# CC3220SF register map
Vendor: Texas Instruments; Series: Wireless Connectivity MCU; File version: 1
CPU: CM4 r1p0, little endian, no MPU, no FPU, 8 interrupt priority bits
Registers are 32-bit, read-write, reset 0x0 unless marked. A register's access mark holds for its fields unless they carry their own. Offsets are from the block's base; [hi:lo] are bit positions; {n}, {i} and the like mark numbered series.

## I2CA0
Base 0x40020000
0x00 MSA
  [7:1] SA — I2C Slave Address
0x04 MCS
0x08 MDR
  [7:0] DATA — Data Transferred
0x0C MTPR
  [6:0] TPR — SCL Clock Period
0x10 MIMR
0x14 MRIS
0x18 MMIS
0x1C MICR
0x20 MCR
0x24 MCLKOCNT
  [7:0] CNTL — I2C Master Count
0x2C MBMON
0x30 MBLEN
  [7:0] CNTL — I2C Burst Length
0x34 MBCNT
  [7:0] CNTL — I2C Master Burst Count
0x800 SOAR
  [6:0] OAR — I2C Slave Own Address
0x804 SCSR
0x808 SDR
  [7:0] DATA — Data for Transfer
0x80C SIMR
0x810 SRIS
0x814 SMIS
0x818 SICR
0x81C SOAR2
  [6:0] OAR2 — I2C Slave Own Address 2
0x820 SACKCTL
0xF00 FIFODATA
  [7:0] DATA — I2C FIFO Data Byte
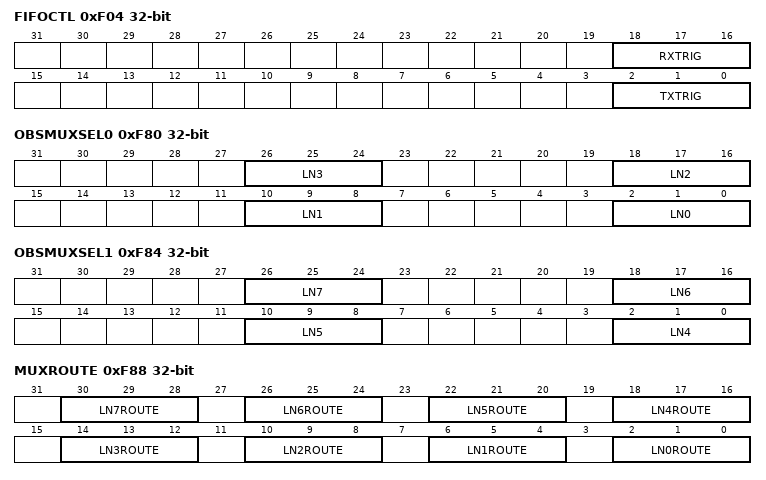
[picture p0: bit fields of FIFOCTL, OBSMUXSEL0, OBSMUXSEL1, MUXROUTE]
0xF04 FIFOCTL
  [18:16] RXTRIG — RX FIFO Trigger
  [2:0] TXTRIG — TX FIFO Trigger
0xF08 FIFOSTATUS
0xF80 OBSMUXSEL0
  [8n+2:8n] LN{n} (n=0..3) — Observation Mux Lane {n}
0xF84 OBSMUXSEL1
  [8n-30:8n-32] LN{n} (n=4..7) — Observation Mux Lane {n}
0xF88 MUXROUTE
  [4n+2:4n] LN{n}ROUTE (n=0..7) — Lane {n} output is routed to the lane pointed to by the offset in this bit field
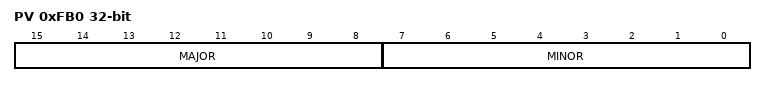
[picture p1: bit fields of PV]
0xFB0 PV
  [15:8] MAJOR — Major Revision
  [7:0] MINOR — Minor Revision
0xFC0 PP
0xFC4 PC
0xFC8 CC

## TIMERA0
Base 0x40030000
Same registers: TIMERA1 0x40031000, TIMERA2 0x40032000, TIMERA3 0x40033000
0x00 CFG — GPTM Configuration
  [2:0] CFG
0x04 TAMR — GPTM Timer A Mode
  [1:0] TAMR
0x08 TBMR — GPTM Timer B Mode
  [1:0] TBMR
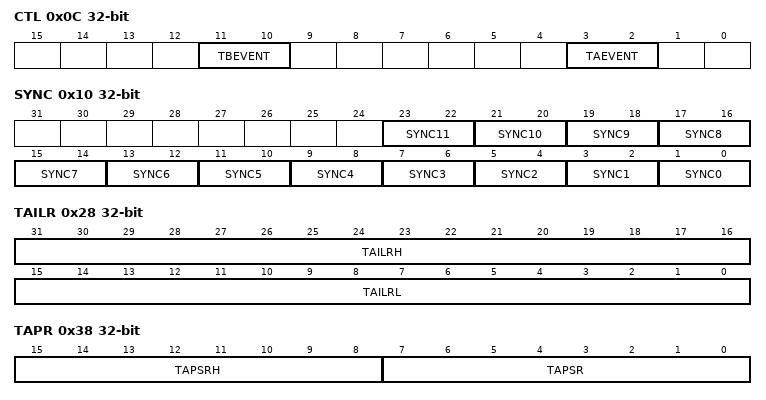
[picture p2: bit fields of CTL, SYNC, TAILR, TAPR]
0x0C CTL — GPTM Control ##### GARNET BEGIN #####
  [11:10] TBEVENT — GPTM Timer B Event Mode
  [3:2] TAEVENT — GPTM Timer A Event Mode
0x10 SYNC — GPTM Synchronize ##### GARNET END #####
  [2n+1:2n] SYNC{n} (n=0..11) — Synchronize GPTM Timer {n}
0x18 IMR — GPTM Interrupt Mask
0x1C RIS — GPTM Raw Interrupt Status
0x20 MIS — GPTM Masked Interrupt Status
0x24 ICR — GPTM Interrupt Clear
0x28 TAILR — GPTM Timer A Interval Load
  [31:16] TAILRH — GPTM Timer A Interval Load Register High
  [15:0] TAILRL — GPTM Timer A Interval Load Register Low
0x2C TBILR — GPTM Timer B Interval Load
  [15:0] TBILRL — GPTM Timer B Interval Load Register
0x30 TAMATCHR — GPTM Timer A Match
0x34 TBMATCHR — GPTM Timer B Match
0x38 TAPR — GPTM Timer A Prescale
  [15:8] TAPSRH — GPTM Timer A Prescale High Byte ##### GARNET END #####
  [7:0] TAPSR — GPTM Timer A Prescale ##### GARNET BEGIN #####
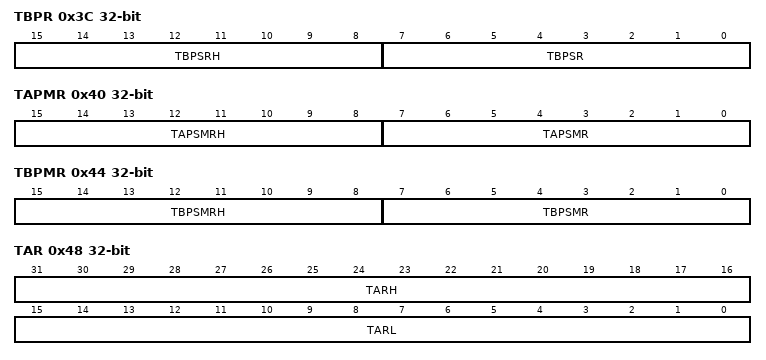
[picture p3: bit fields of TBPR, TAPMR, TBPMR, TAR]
0x3C TBPR — GPTM Timer B Prescale
  [15:8] TBPSRH — GPTM Timer B Prescale High Byte ##### GARNET END #####
  [7:0] TBPSR — GPTM Timer B Prescale ##### GARNET BEGIN #####
0x40 TAPMR — GPTM TimerA Prescale Match
  [15:8] TAPSMRH — GPTM Timer A Prescale Match High Byte ##### GARNET END #####
  [7:0] TAPSMR — GPTM TimerA Prescale Match ##### GARNET BEGIN #####
0x44 TBPMR — GPTM TimerB Prescale Match
  [15:8] TBPSMRH — GPTM Timer B Prescale Match High Byte ##### GARNET END #####
  [7:0] TBPSMR — GPTM TimerB Prescale Match ##### GARNET BEGIN #####
0x48 TAR — GPTM Timer A
  [31:16] TARH — GPTM Timer A Register High
  [15:0] TARL — GPTM Timer A Register Low
0x4C TBR — GPTM Timer B
  [23:0] TBRL
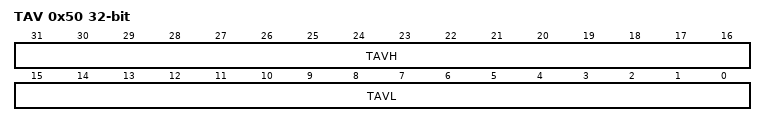
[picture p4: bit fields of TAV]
0x50 TAV — GPTM Timer A Value
  [31:16] TAVH — GPTM Timer A Value High
  [15:0] TAVL — GPTM Timer A Register Low
0x54 TBV — GPTM Timer B Value
  [15:0] TBVL — GPTM Timer B Register
0x58 RTCPD — GPTM RTC Predivide
  [15:0] RTCPD — RTC Predivide Counter Value
0x5C TAPS — GPTM Timer A Prescale Snapshot
  [15:0] PSS — GPTM Timer A Prescaler Snapshot
0x60 TBPS — GPTM Timer B Prescale Snapshot
  [15:0] PSS — GPTM Timer A Prescaler Value
0x64 TAPV — GPTM Timer A Prescale Value
  [15:0] PSV — GPTM Timer A Prescaler Value
0x68 TBPV — GPTM Timer B Prescale Value
  [15:0] PSV — GPTM Timer B Prescaler Value
0x6C DMAEV — GPTM DMA Event
0xFC0 PP — GPTM Peripheral Properties ***************************************************************************
  [3:0] SIZE — Count Size
